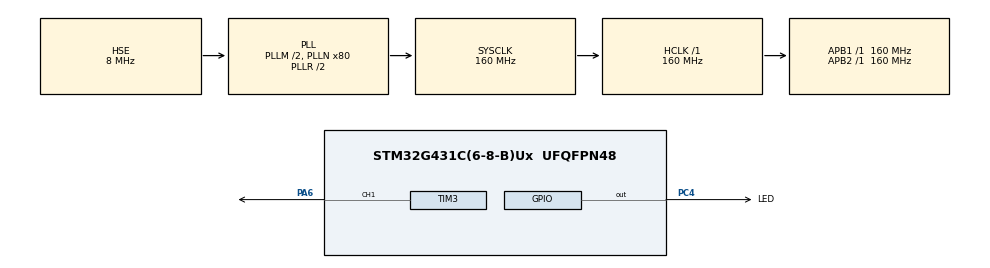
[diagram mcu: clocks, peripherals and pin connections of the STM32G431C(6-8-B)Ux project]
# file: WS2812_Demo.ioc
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Dma.Request0=TIM3_CH1
Dma.TIM3_CH1.0.Direction=DMA_MEMORY_TO_PERIPH
Dma.TIM3_CH1.0.EventEnable=DISABLE
Dma.TIM3_CH1.0.Instance=DMA1_Channel1
Dma.TIM3_CH1.0.MemDataAlignment=DMA_MDATAALIGN_HALFWORD
Dma.TIM3_CH1.0.MemInc=DMA_MINC_ENABLE
Dma.TIM3_CH1.0.Mode=DMA_NORMAL
Dma.TIM3_CH1.0.PeriphDataAlignment=DMA_PDATAALIGN_HALFWORD
Dma.TIM3_CH1.0.PeriphInc=DMA_PINC_DISABLE
Dma.TIM3_CH1.0.Polarity=HAL_DMAMUX_REQ_GEN_RISING
Dma.TIM3_CH1.0.Priority=DMA_PRIORITY_LOW
Dma.TIM3_CH1.0.RequestNumber=1
Dma.TIM3_CH1.0.SignalID=NONE
Dma.TIM3_CH1.0.SyncEnable=DISABLE
Dma.TIM3_CH1.0.SyncPolarity=HAL_DMAMUX_SYNC_NO_EVENT
Dma.TIM3_CH1.0.SyncRequestNumber=1
Dma.TIM3_CH1.0.SyncSignalID=NONE
Mcu.Family=STM32G4
Mcu.Name=STM32G431C(6-8-B)Ux
Mcu.Package=UFQFPN48
NVIC.DMA1_Channel1_IRQn=true\:0\:0\:false\:false\:true\:false\:true\:true
NVIC.PriorityGroup=NVIC_PRIORITYGROUP_4
PA13.Mode=Serial_Wire
PA13.Signal=SYS_JTMS-SWDIO
PA14.Mode=Serial_Wire
PA14.Signal=SYS_JTCK-SWCLK
PA6.Signal=S_TIM3_CH1
PC4.GPIO_Label=LED
PC4.GPIO_Speed=GPIO_SPEED_FREQ_VERY_HIGH
PC4.PinState=GPIO_PIN_SET
PC4.Signal=GPIO_Output
PF0-OSC_IN.Mode=HSE-External-Oscillator
PF0-OSC_IN.Signal=RCC_OSC_IN
PF1-OSC_OUT.Mode=HSE-External-Oscillator
PF1-OSC_OUT.Signal=RCC_OSC_OUT
ProjectManager.HeapSize=0x200
ProjectManager.StackSize=0x400
ProjectManager.TargetToolchain=MDK-ARM V5.32
RCC.ADC12Freq_Value=160000000
RCC.AHBFreq_Value=160000000
RCC.APB1Freq_Value=160000000
RCC.APB1TimFreq_Value=160000000
RCC.APB2Freq_Value=160000000
RCC.APB2TimFreq_Value=160000000
RCC.CortexFreq_Value=160000000
RCC.EXTERNAL_CLOCK_VALUE=12288000
RCC.HCLKFreq_Value=160000000
RCC.HSE_VALUE=8000000
RCC.HSI48_VALUE=48000000
RCC.HSI_VALUE=16000000
RCC.LSE_VALUE=32768
RCC.PLLM=RCC_PLLM_DIV2
RCC.PLLN=80
RCC.PLLSourceVirtual=RCC_PLLSOURCE_HSE
RCC.SYSCLKFreq_VALUE=160000000
RCC.SYSCLKSource=RCC_SYSCLKSOURCE_PLLCLK
RCC.USBFreq_Value=160000000
RCC.VCOOutputFreq_Value=320000000
SH.S_TIM3_CH1.0=TIM3_CH1,PWM Generation1 CH1
TIM3.Channel-PWM\ Generation1\ CH1=TIM_CHANNEL_1
TIM3.PeriodNoDither=200-1
TIM3.Prescaler=1-1
VP_SYS_VS_DBSignals.Mode=DisableDeadBatterySignals
VP_TIM3_VS_ClockSourceINT.Mode=Internal
board=custom

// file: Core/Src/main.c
/* USER CODE BEGIN Header */
/**
  ******************************************************************************
  * @file           : main.c
  * @brief          : Main program body
  ******************************************************************************
  * @attention
  *
  * Copyright (c) 2023 STMicroelectronics.
  * All rights reserved.
  *
  * This software is licensed under terms that can be found in the LICENSE file
  * in the root directory of this software component.
  * If no LICENSE file comes with this software, it is provided AS-IS.
  *
  ******************************************************************************
  */
/* USER CODE END Header */
#include "main.h"
#include "dma.h"
#include "tim.h"
#include "gpio.h"

/* USER CODE BEGIN Includes */
#include "WS2812.h"
/* USER CODE END Includes */

/* USER CODE BEGIN PV */
uint8_t brightness=50;
/* USER CODE END PV */

void SystemClock_Config(void);

int main(void)
{
  /* USER CODE BEGIN 1 */
	uint8_t i;
  /* USER CODE END 1 */

  /* MCU Configuration--------------------------------------------------------*/

  /* Reset of all peripherals, Initializes the Flash interface and the Systick. */
  HAL_Init();

  /* Configure the system clock */
  SystemClock_Config();

  /* Initialize all configured peripherals */
  MX_GPIO_Init();
  MX_DMA_Init();
  MX_TIM3_Init();
  /* USER CODE BEGIN 2 */
  WS_CloseAll();
	WS_WriteAll_RGB(0xff,0,0,brightness);
	HAL_GPIO_TogglePin(LED_GPIO_Port,LED_Pin);
	HAL_Delay(1000);
	WS_CloseAll();

  /* USER CODE END 2 */

  /* Infinite loop */
  /* USER CODE BEGIN WHILE */
  while (1)
  {
		for(i=0;i<101;i++)
		{
			brightness=i;
			WS_WriteOne_RGB(1,0,0,0xff,brightness);
			HAL_Delay(30);
		}
    /* USER CODE END WHILE */

  }
}

void SystemClock_Config(void)
{
  RCC_OscInitTypeDef RCC_OscInitStruct = {0};
  RCC_ClkInitTypeDef RCC_ClkInitStruct = {0};

  /** Configure the main internal regulator output voltage
  */
  HAL_PWREx_ControlVoltageScaling(PWR_REGULATOR_VOLTAGE_SCALE1_BOOST);

  /** Initializes the RCC Oscillators according to the specified parameters
  * in the RCC_OscInitTypeDef structure.
  */
  RCC_OscInitStruct.OscillatorType = RCC_OSCILLATORTYPE_HSE;
  RCC_OscInitStruct.HSEState = RCC_HSE_ON;
  RCC_OscInitStruct.PLL.PLLState = RCC_PLL_ON;
  RCC_OscInitStruct.PLL.PLLSource = RCC_PLLSOURCE_HSE;
  RCC_OscInitStruct.PLL.PLLM = RCC_PLLM_DIV2;
  RCC_OscInitStruct.PLL.PLLN = 80;
  RCC_OscInitStruct.PLL.PLLP = RCC_PLLP_DIV2;
  RCC_OscInitStruct.PLL.PLLQ = RCC_PLLQ_DIV2;
  RCC_OscInitStruct.PLL.PLLR = RCC_PLLR_DIV2;
  if (HAL_RCC_OscConfig(&RCC_OscInitStruct) != HAL_OK)
  {
    Error_Handler();
  }

  /** Initializes the CPU, AHB and APB buses clocks
  */
  RCC_ClkInitStruct.ClockType = RCC_CLOCKTYPE_HCLK|RCC_CLOCKTYPE_SYSCLK
                              |RCC_CLOCKTYPE_PCLK1|RCC_CLOCKTYPE_PCLK2;
  RCC_ClkInitStruct.SYSCLKSource = RCC_SYSCLKSOURCE_PLLCLK;
  RCC_ClkInitStruct.AHBCLKDivider = RCC_SYSCLK_DIV1;
  RCC_ClkInitStruct.APB1CLKDivider = RCC_HCLK_DIV1;
  RCC_ClkInitStruct.APB2CLKDivider = RCC_HCLK_DIV1;

  if (HAL_RCC_ClockConfig(&RCC_ClkInitStruct, FLASH_LATENCY_4) != HAL_OK)
  {
    Error_Handler();
  }
}

void Error_Handler(void)
{
  __disable_irq();
  while (1)
  {
  }
}
